AUTOSAR XML (schema 4-1-3)
standard types defined: boolean, sint16, uint16, uint32, uint8, uint8_DataConstr
package /UAES/ASW/ApplicationDataTypes
  4 x app type, all with category=VALUE, sw-calibration-access=READ-WRITE:
    Frq_q0p1_Hz_u16: compu {phys=raw*0.1 for raw -INF..INF; unit Hz}, range raw 0..65535
    I_q0p25_mA_s16: compu {phys=raw*0.25 for raw -INF..INF; unit mA}, range raw -32768..32767
    Perc_q0p0122_Perc_s16: compu {phys=raw*0.01220703125 for raw -INF..INF; unit %}, range raw -32768..32767
    Ti_q1_us_u32: compu {phys=raw for raw -INF..INF; unit us}, range phys 0..4294967295, raw 0..4294967295
package /UAES/ASW/CompuMethods
  compu method CM_boolean: 0=FALSE, 1=TRUE
package /UAES/ASW/DataConstrs
  range DC_boolean: raw 0..1
  range DC_sint16: raw -32768..32767
  range DC_uint16: phys 0..6553.5, raw 0..65535
  range DC_uint32: raw 0..4294967295
package /UAES/ASW/DataTypeMappingSets
  data type mapping set DTMS_ChrgMngt_ComCnvRx
    data-type-maps:
      application-data-type=Frq_q0p1_Hz_u16, implementation-data-type=uint16
      application-data-type=I_q0p25_mA_s16, implementation-data-type=sint16
      application-data-type=Perc_q0p0122_Perc_s16, implementation-data-type=sint16
      application-data-type=Ti_q1_us_u32, implementation-data-type=uint32
package /UAES/ASW/PortInterfaces
  15 x sender receiver interface:
    BattU_bVoltEnbPinDiag: invalidation-policy{data-element=BattU_bVoltEnbPinDiag/Val, handle-invalid=DONT-INVALIDATE}
      data Val: sw-calibration-access=READ-ONLY, type=boolean
    ChgrPlug_stPlgLock: invalidation-policy{data-element=ChgrPlug_stPlgLock/Val, handle-invalid=DONT-INVALIDATE}
      data Val: sw-calibration-access=READ-ONLY, type=ImplementationDataTypes/uint8
    ChrgIndcr_stCtrlTyp: invalidation-policy{data-element=ChrgIndcr_stCtrlTyp/Val, handle-invalid=DONT-INVALIDATE}
      data Val: sw-calibration-access=READ-ONLY, type=ImplementationDataTypes/uint8
    ChrgIndcr_stReq: invalidation-policy{data-element=ChrgIndcr_stReq/Val, handle-invalid=DONT-INVALIDATE}
      data Val: sw-calibration-access=READ-ONLY, type=ImplementationDataTypes/uint8
    ChrgPlg_stPlgLockCmd: invalidation-policy{data-element=ChrgPlg_stPlgLockCmd/Val, handle-invalid=DONT-INVALIDATE}
      data Val: sw-calibration-access=READ-ONLY, type=ImplementationDataTypes/uint8
    ComRx_bVCU_ElecUnlockDrvReq_A02_TiOut: invalidation-policy{data-element=ComRx_bVCU_ElecUnlockDrvReq_A02_TiOut/Val, handle-invalid=DONT-INVALIDATE}
      data Val: sw-calibration-access=READ-ONLY, type=boolean
    ComRx_bVCU_ElecUnlockDrvReq_A09_TiOut: invalidation-policy{data-element=ComRx_bVCU_ElecUnlockDrvReq_A09_TiOut/Val, handle-invalid=DONT-INVALIDATE}
      data Val: sw-calibration-access=READ-ONLY, type=boolean
    ComRx_u8VCU_Chglampflashreq: invalidation-policy{data-element=ComRx_u8VCU_Chglampflashreq/Val, handle-invalid=DONT-INVALIDATE}
      data Val: sw-calibration-access=READ-ONLY, type=ImplementationDataTypes/uint8
    ComRx_u8VCU_Chglamplightreq: invalidation-policy{data-element=ComRx_u8VCU_Chglamplightreq/Val, handle-invalid=DONT-INVALIDATE}
      data Val: sw-calibration-access=READ-ONLY, type=ImplementationDataTypes/uint8
    ComRx_u8VCU_ElecUnlockDrvReq: invalidation-policy{data-element=ComRx_u8VCU_ElecUnlockDrvReq/Val, handle-invalid=DONT-INVALIDATE}
      data Val: sw-calibration-access=READ-ONLY, type=ImplementationDataTypes/uint8
    ComRx_u8VCU_ElecUnlockDrvReq_A02: invalidation-policy{data-element=ComRx_u8VCU_ElecUnlockDrvReq_A02/Val, handle-invalid=DONT-INVALIDATE}
      data Val: sw-calibration-access=READ-ONLY, type=ImplementationDataTypes/uint8
    ComRx_u8VCU_ElecUnlockDrvReq_A09: invalidation-policy{data-element=ComRx_u8VCU_ElecUnlockDrvReq_A09/Val, handle-invalid=DONT-INVALIDATE}
      data Val: sw-calibration-access=READ-ONLY, type=ImplementationDataTypes/uint8
    ComRx_u8VCU_ElecUnlockDrvReq_XH2: invalidation-policy{data-element=ComRx_u8VCU_ElecUnlockDrvReq_XH2/Val, handle-invalid=DONT-INVALIDATE}
      data Val: sw-calibration-access=READ-ONLY, type=ImplementationDataTypes/uint8
    gPRM_u8VehicleTypeCfg: invalidation-policy{data-element=gPRM_u8VehicleTypeCfg/Val, handle-invalid=DONT-INVALIDATE}
      data Val: sw-calibration-access=READ-ONLY, range raw 0..255, type=ImplementationDataTypes/uint8
    VehCoorn_stPwrMod: invalidation-policy{data-element=VehCoorn_stPwrMod/Val, handle-invalid=DONT-INVALIDATE}
      data Val: sw-calibration-access=READ-ONLY, type=ImplementationDataTypes/uint8
package /UAES/ASW/Units
  5 x unit, all with factor-si-to-unit=1, offset-si-to-unit=0:
    Hz: display-name=Hz
    mA: display-name=mA
    NoUnit
    Perc: display-name=%
    us: display-name=us
package /UAES/SwComponentTypes
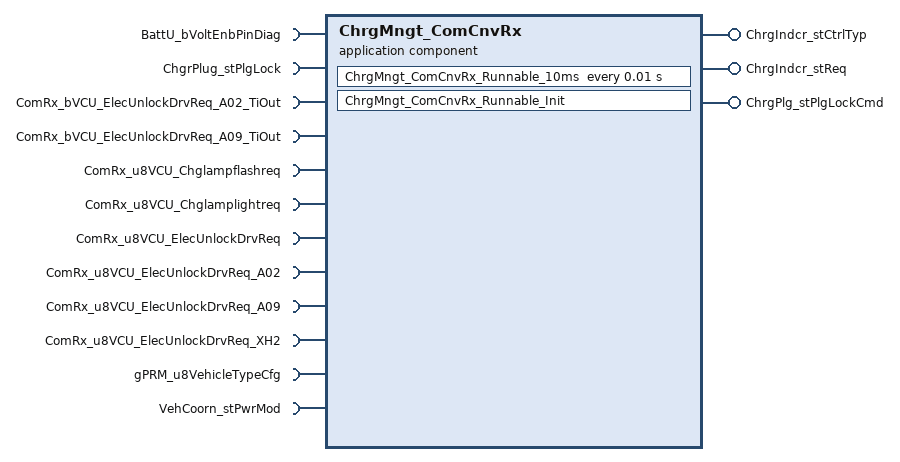
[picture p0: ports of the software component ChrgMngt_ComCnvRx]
  application sw component type ChrgMngt_ComCnvRx
    provide port ChrgIndcr_stCtrlTyp: nonqueued-sender-com-spec{data-element=ChrgIndcr_stCtrlTyp/Val, init-value=0}, provided-interface=ChrgIndcr_stCtrlTyp
    provide port ChrgIndcr_stReq: nonqueued-sender-com-spec{data-element=ChrgIndcr_stReq/Val, init-value=0}, provided-interface=ChrgIndcr_stReq
    provide port ChrgPlg_stPlgLockCmd: nonqueued-sender-com-spec{data-element=ChrgPlg_stPlgLockCmd/Val, init-value=0}, provided-interface=ChrgPlg_stPlgLockCmd
    12 x require port:
      BattU_bVoltEnbPinDiag: nonqueued-receiver-com-spec{data-element=BattU_bVoltEnbPinDiag/Val, filter=data-filter-type=ALWAYS, init-value=0}, required-interface=BattU_bVoltEnbPinDiag
      ChgrPlug_stPlgLock: nonqueued-receiver-com-spec{data-element=ChgrPlug_stPlgLock/Val, filter=data-filter-type=ALWAYS, init-value=0}, required-interface=ChgrPlug_stPlgLock
      ComRx_bVCU_ElecUnlockDrvReq_A02_TiOut: nonqueued-receiver-com-spec{data-element=ComRx_bVCU_ElecUnlockDrvReq_A02_TiOut/Val, filter=data-filter-type=ALWAYS, init-value=0}, required-interface=ComRx_bVCU_ElecUnlockDrvReq_A02_TiOut
      ComRx_bVCU_ElecUnlockDrvReq_A09_TiOut: nonqueued-receiver-com-spec{data-element=ComRx_bVCU_ElecUnlockDrvReq_A09_TiOut/Val, filter=data-filter-type=ALWAYS, init-value=0}, required-interface=ComRx_bVCU_ElecUnlockDrvReq_A09_TiOut
      ComRx_u8VCU_Chglampflashreq: nonqueued-receiver-com-spec{data-element=ComRx_u8VCU_Chglampflashreq/Val, filter=data-filter-type=ALWAYS, init-value=0}, required-interface=ComRx_u8VCU_Chglampflashreq
      ComRx_u8VCU_Chglamplightreq: nonqueued-receiver-com-spec{data-element=ComRx_u8VCU_Chglamplightreq/Val, filter=data-filter-type=ALWAYS, init-value=0}, required-interface=ComRx_u8VCU_Chglamplightreq
      ComRx_u8VCU_ElecUnlockDrvReq: nonqueued-receiver-com-spec{data-element=ComRx_u8VCU_ElecUnlockDrvReq/Val, filter=data-filter-type=ALWAYS, init-value=0}, required-interface=ComRx_u8VCU_ElecUnlockDrvReq
      ComRx_u8VCU_ElecUnlockDrvReq_A02: nonqueued-receiver-com-spec{data-element=ComRx_u8VCU_ElecUnlockDrvReq_A02/Val, filter=data-filter-type=ALWAYS, init-value=0}, required-interface=ComRx_u8VCU_ElecUnlockDrvReq_A02
      ComRx_u8VCU_ElecUnlockDrvReq_A09: nonqueued-receiver-com-spec{data-element=ComRx_u8VCU_ElecUnlockDrvReq_A09/Val, filter=data-filter-type=ALWAYS, init-value=0}, required-interface=ComRx_u8VCU_ElecUnlockDrvReq_A09
      ComRx_u8VCU_ElecUnlockDrvReq_XH2: nonqueued-receiver-com-spec{data-element=ComRx_u8VCU_ElecUnlockDrvReq_XH2/Val, filter=data-filter-type=ALWAYS, init-value=0}, required-interface=ComRx_u8VCU_ElecUnlockDrvReq_XH2
      gPRM_u8VehicleTypeCfg: nonqueued-receiver-com-spec{data-element=gPRM_u8VehicleTypeCfg/Val, filter=data-filter-type=ALWAYS, init-value=0}, required-interface=gPRM_u8VehicleTypeCfg
      VehCoorn_stPwrMod: nonqueued-receiver-com-spec{data-element=VehCoorn_stPwrMod/Val, filter=data-filter-type=ALWAYS, init-value=0}, required-interface=VehCoorn_stPwrMod
    behavior ChrgMngt_ComCnvRx_InternalBehavior: data-type-mapping=DTMS_ChrgMngt_ComCnvRx
      timing event TMT_ChrgMngt_ComCnvRx_Runnable_10ms: start-on-event=ChrgMngt_ComCnvRx_Runnable_10ms, period=0.01
      init event ChrgMngt_ComCnvRx_InitEvent: start-on-event=ChrgMngt_ComCnvRx_Runnable_Init
      runnable ChrgMngt_ComCnvRx_Runnable_10ms
        data-read-access:
          12 x access:
            READ_BattU_bVoltEnbPinDiag_Val: accessed-variable=BattU_bVoltEnbPinDiag.Val
            READ_ChgrPlug_stPlgLock_Val: accessed-variable=ChgrPlug_stPlgLock.Val
            READ_ComRx_bVCU_ElecUnlockDrvReq_A02_TiOut_Val: accessed-variable=ComRx_bVCU_ElecUnlockDrvReq_A02_TiOut.Val
            READ_ComRx_bVCU_ElecUnlockDrvReq_A09_TiOut_Val: accessed-variable=ComRx_bVCU_ElecUnlockDrvReq_A09_TiOut.Val
            READ_ComRx_u8VCU_Chglampflashreq_Val: accessed-variable=ComRx_u8VCU_Chglampflashreq.Val
            READ_ComRx_u8VCU_Chglamplightreq_Val: accessed-variable=ComRx_u8VCU_Chglamplightreq.Val
            READ_ComRx_u8VCU_ElecUnlockDrvReq_A02_Val: accessed-variable=ComRx_u8VCU_ElecUnlockDrvReq_A02.Val
            READ_ComRx_u8VCU_ElecUnlockDrvReq_A09_Val: accessed-variable=ComRx_u8VCU_ElecUnlockDrvReq_A09.Val
            READ_ComRx_u8VCU_ElecUnlockDrvReq_Val: accessed-variable=ComRx_u8VCU_ElecUnlockDrvReq.Val
            READ_ComRx_u8VCU_ElecUnlockDrvReq_XH2_Val: accessed-variable=ComRx_u8VCU_ElecUnlockDrvReq_XH2.Val
            READ_gPRM_u8VehicleTypeCfg_Val: accessed-variable=gPRM_u8VehicleTypeCfg.Val
            READ_VehCoorn_stPwrMod_Val: accessed-variable=VehCoorn_stPwrMod.Val
        data-write-access:
          access WRITE_ChrgIndcr_stCtrlTyp_Val: accessed-variable=ChrgIndcr_stCtrlTyp.Val
          access WRITE_ChrgIndcr_stReq_Val: accessed-variable=ChrgIndcr_stReq.Val
          access WRITE_ChrgPlg_stPlgLockCmd_Val: accessed-variable=ChrgPlg_stPlgLockCmd.Val
      runnable ChrgMngt_ComCnvRx_Runnable_Init
  swc implementation ChrgMngt_ComCnvRx_Implementation: behavior=ChrgMngt_ComCnvRx_InternalBehavior
    code-descriptors:
      code Default: artifact-descriptors=autosar-engineering-object={short-label=Default, category=SWSRC}
